# TC37XPD register map
Vendor: Infineon; Series: ATVMC; File version: 100
CPU: other r0p0, little endian, MPU, FPU, vendor SysTick, 4 interrupt priority bits
Registers are 32-bit, read-write, reset 0x0 unless marked. A register's access mark holds for its fields unless they carry their own. Offsets are from the block's base; [hi:lo] are bit positions; {n}, {i} and the like mark numbered series.

## CCU60 — CCU6
Base 0xF0002A00
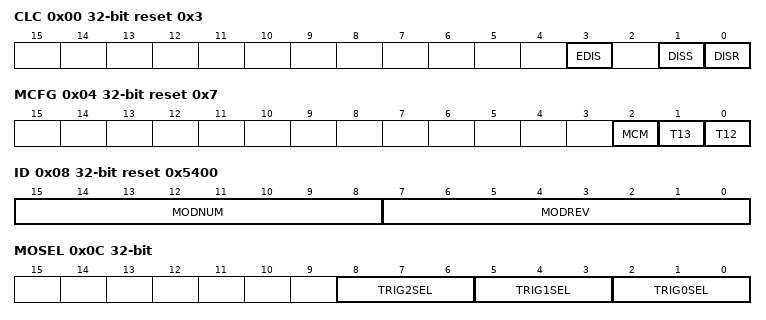
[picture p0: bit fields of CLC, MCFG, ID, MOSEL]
0x00 CLC access per field reset 0x3 — Clock Control Register resetvalue={Application Reset:0x3}
  [3] EDIS rw — Sleep Mode Enable Control EDIS. Used to control module 8217 s sleep mode.
  [1] DISS ro — Module Disable Status Bit DISS. Bit indicates the current status of the module.
  [0] DISR rw — Module Disable Request Bit DISR. Used for enable disable control of the module.
0x04 MCFG ro reset 0x7 — Module Configuration Register resetvalue={Application Reset:0x08007,Application Reset:0x7}
  [2] MCM — Multi Channel Mode Available MCM. This bit indicates if the multi channel mode functionality is available.
  [1] T13 — T13 Available T13. This bit indicates if the T13 block is available.
  [0] T12 — T12 Available T12. This bit indicates if the T12 block is available.
0x08 ID ro reset 0x5400 (reset mask 0xFFFFFF00) — Module Identification Register resetvalue={Application Reset:0x5400,Application Reset:0x5409}
  [15:8] MODNUM — Module Number Value MODNUM. This bit field defines the module identification number for the CCU6 54 H
  [7:0] MODREV — Module Revision Number MODREV. MODREV defines the module revision number. The value of a module revision starts with 01 H first revision 02 H 03 H 8230 up to FF H .
0x0C MOSEL — CCU60 Module Output Select Register resetvalue={Application Reset:0x0}
  [8:6] TRIG2SEL — Output Trigger Select for CCU6061 TRIG2. This bit field defines the output signal from the CCU6061 module used as the trigger signal to the EVADC inputs.
  [5:3] TRIG1SEL — Output Trigger Select for CCU6061 TRIG2. This bit field defines the output signal from the CCU6061 module used as the trigger signal to the EVADC inputs.
  [2:0] TRIG0SEL — Output Trigger Select for CCU6061 TRIG2. This bit field defines the output signal from the CCU6061 module used as the trigger signal to the EVADC inputs.
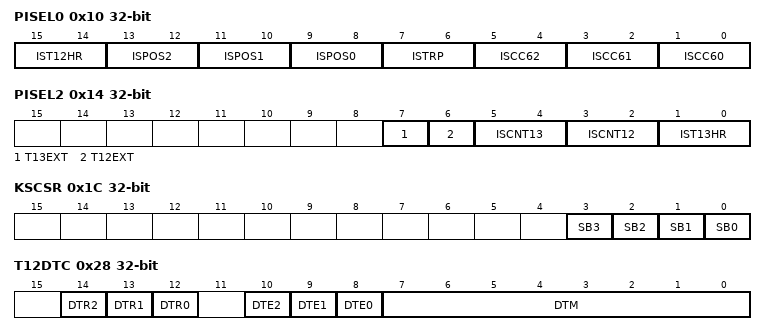
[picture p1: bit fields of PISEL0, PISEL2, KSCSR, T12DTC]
0x10 PISEL0 — Port Input Select Register 0 resetvalue={Application Reset:0x0}
  [15:14] IST12HR — Input Select for T12HR IST12HR. This bit field defines the input signal used as T12HR input.
  [13:12] ISPOS2 — Input Select for CCPOS0 ISPOSx x 0 1 2 . This bit field defines the input signal used as CCPOSx input.
  [11:10] ISPOS1 — Input Select for CCPOS0 ISPOSx x 0 1 2 . This bit field defines the input signal used as CCPOSx input.
  [9:8] ISPOS0 — Input Select for CCPOS0 ISPOSx x 0 1 2 . This bit field defines the input signal used as CCPOSx input.
  [7:6] ISTRP — Input Select for CTRAP ISTRP. This bit field defines the input signal used as CTRAP input.
  [5:4] ISCC62 — Input Select for CC60 ISCC6x x 0 1 2 . This bit field defines the input signal used as CC6x capture input.
  [3:2] ISCC61 — Input Select for CC60 ISCC6x x 0 1 2 . This bit field defines the input signal used as CC6x capture input.
  [1:0] ISCC60 — Input Select for CC60 ISCC6x x 0 1 2 . This bit field defines the input signal used as CC6x capture input.
0x14 PISEL2 — Port Input Select Register 2 resetvalue={Application Reset:0x0}
  [7] T13EXT — Extension for T13HR Inputs T13EXT. This bit extends the 2 bit field IST13HR.
  [6] T12EXT — Extension for T12HR Inputs T12EXT. This bit extends the 2 bit field IST12HR.
  [5:4] ISCNT13 — Input Select for T13 Counting Input ISCNT13. This bit field defines the input event leading to a counting action of T13.
  [3:2] ISCNT12 — Input Select for T12 Counting Input ISCNT12. This bit field defines the input event leading to a counting action of T12.
  [1:0] IST13HR — Input Select for T13HR IST13HR. This bit field defines the input signal used as T13HR input.
0x1C KSCSR — Kernel State Control Sensitivity Register resetvalue={PowerOn Reset:0x0,Debug Reset:0x0}
  [n] SB{n} (n=0..3) — Sensitivity Block x SBx x 0 1 2 3 . This bit defines if block x of the CCU6 kernel is sensitive to Stop Mode 0 or Stop Mode 1. The functional definition of the blocks is given in CROSSREFERENCE .
0x20 T12 — Timer T12 Counter Register resetvalue={Application Reset:0x0}
  [15:0] T12CV — Timer 12 Counter Value T12CV. This register represents the 16 bit counter value of Timer12.
0x24 T12PR — Timer 12 Period Register resetvalue={Application Reset:0x0}
  [15:0] T12PV — T12 Period Value T12PV. The value T12PV defines the counter value for T12 leading to a period match. When reaching this value the timer T12 is set to zero edge aligned mode or changes its count direction to down counting center aligned mode .
0x28 T12DTC access per field — Dead Time Control Register for Timer12 resetvalue={Application Reset:0x0}
  [14] DTR2 ro — Dead Time Run Indication Bits DTRx x 1 2 3 . Bits DTR0 8230 DTR2 indicate the status of the dead time generation for each compare channel 0 1 2 of timer T12.
  [13] DTR1 ro — Dead Time Run Indication Bits DTRx x 1 2 3 . Bits DTR0 8230 DTR2 indicate the status of the dead time generation for each compare channel 0 1 2 of timer T12.
  [12] DTR0 ro — Dead Time Run Indication Bits DTRx x 1 2 3 . Bits DTR0 8230 DTR2 indicate the status of the dead time generation for each compare channel 0 1 2 of timer T12.
  [10] DTE2 rw — Dead Time Enable Bits DTEx x 0 1 2 . Bits DTE0 8230 DTE2 enable and disable the dead time generation for each compare channel 0 1 2 of timer T12.
  [9] DTE1 rw — Dead Time Enable Bits DTEx x 0 1 2 . Bits DTE0 8230 DTE2 enable and disable the dead time generation for each compare channel 0 1 2 of timer T12.
  [8] DTE0 rw — Dead Time Enable Bits DTEx x 0 1 2 . Bits DTE0 8230 DTE2 enable and disable the dead time generation for each compare channel 0 1 2 of timer T12.
  [7:0] DTM rw — Dead Time DTM. Bit field DTM determines the programmable delay between switching from the passive state to the active state of the selected outputs. The switching from the active state to the passive state is not delayed.
{0x30+4i} CC6xR[{i}] (i=0..2) ro — Capture Compare Register for Channel CC60 resetvalue={Application Reset:0x0}
  [15:0] CCV — Capture Compare Value CCV. In compare mode the bit fields CCV contain the values that are compared to the T12 counter value. In capture mode the captured value of T12 can be read from these registers.
{0x40+4i} CC6xSR[{i}] (i=0..2) — Capture Compare Shadow Reg. for Channel CC60 resetvalue={Application Reset:0x0}
  [15:0] CCS — Shadow Register for Channel x Capture Compare Value CCS. In compare mode the bit fields contents of CCS are transferred to the bit fields CCV for the corresponding channel during a shadow transfer. In capture mode the captured value of T12 can be read from these registers.
0x50 T13 — Timer T13 Counter Register resetvalue={Application Reset:0x0}
  [15:0] T13CV — Timer 13 Counter Value T13CV. This register represents the 16 bit counter value of Timer13.
0x54 T13PR — Timer 13 Period Register resetvalue={Application Reset:0x0}
  [15:0] T13PV — T13 Period Value T13PV. The value T13PV defines the counter value for T13 leading to a period match. When reaching this value the timer T13 is set to zero.
0x58 CC63R ro — Compare Register for T13 resetvalue={Application Reset:0x0}
  [15:0] CCV — Channel CC63 Compare Value CCV. The bit field CCV contains the value that is compared to the T13 counter value.
0x5C CC63SR — Compare Shadow Register for T13 resetvalue={Application Reset:0x0}
  [15:0] CCS — Shadow Register for Channel CC63 Compare Value CCS. The bit field contents of CCS is transferred to the bit field CCV during a shadow transfer.
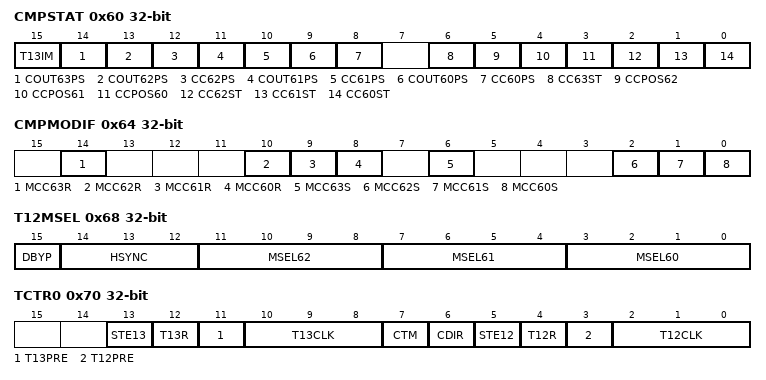
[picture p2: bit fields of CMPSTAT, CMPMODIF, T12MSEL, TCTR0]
0x60 CMPSTAT access per field — Compare State Register resetvalue={Application Reset:0x0}
  [15] T13IM rw — T13 Inverted Modulation T13IM. Bit T13IM inverts the T13 signal for the modulation of the CC6x and COUT6x x 0 1 2 signals.
  [14] COUT63PS rw — Passive State Select for Compare Output COUT63 COUT63PS. Bit COUT63PS selects the state of the corresponding compare channel that is considered to be the passive state. During the passive state the passive level defined in register PSLR is driven by the output pin. Bit COUT63PS is related to T13.
  [13] COUT62PS rw — Passive State Select for Compare Outputs COUT62 x 0 1 2 COUT62PS. Bits COUT6xPS select the state of the corresponding compare channel that is considered to be the passive state. During the passive state the passive level defined in register PSLR is driven by the output pin. Bits COUT6xPS x 0 1 2 are related to T12. In capture mode these bits are not used.
  [12] CC62PS rw — Passive State Select for Compare Outputs CC62 x 0 1 2 CC62PS. Bits CC6xPS select the state of the corresponding compare channel that is considered to be the passive state. During the passive state the passive level defined in register PSLR is driven by the output pin. Bits CC6xPS x 0 1 2 are related to T12. In capture mode these bits are not used.
  [11] COUT61PS rw — Passive State Select for Compare Outputs COUT62 x 0 1 2 COUT62PS. Bits COUT6xPS select the state of the corresponding compare channel that is considered to be the passive state. During the passive state the passive level defined in register PSLR is driven by the output pin. Bits COUT6xPS x 0 1 2 are related to T12. In capture mode these bits are not used.
  [10] CC61PS rw — Passive State Select for Compare Outputs CC62 x 0 1 2 CC62PS. Bits CC6xPS select the state of the corresponding compare channel that is considered to be the passive state. During the passive state the passive level defined in register PSLR is driven by the output pin. Bits CC6xPS x 0 1 2 are related to T12. In capture mode these bits are not used.
  [9] COUT60PS rw — Passive State Select for Compare Outputs COUT62 x 0 1 2 COUT62PS. Bits COUT6xPS select the state of the corresponding compare channel that is considered to be the passive state. During the passive state the passive level defined in register PSLR is driven by the output pin. Bits COUT6xPS x 0 1 2 are related to T12. In capture mode these bits are not used.
  [8] CC60PS rw — Passive State Select for Compare Outputs CC62 x 0 1 2 CC62PS. Bits CC6xPS select the state of the corresponding compare channel that is considered to be the passive state. During the passive state the passive level defined in register PSLR is driven by the output pin. Bits CC6xPS x 0 1 2 are related to T12. In capture mode these bits are not used.
  [6] CC63ST ro — Capture Compare State Bit for CC63 CC63ST. Bit CC63ST monitors the state of the compare channel. Bit CC63ST is related to T13 and is set and cleared according to the T13 switching rules.
  [5] CCPOS62 ro — Sampled Hall Pattern Bits CCPOS62. Bits CCPOS6x x 0 1 2 are indicating the value of the input Hall pattern that has been compared to the current and expected value. The value is sampled when the event HCRDY Hall Compare Ready occurs.
  [4] CCPOS61 ro — Sampled Hall Pattern Bits CCPOS62. Bits CCPOS6x x 0 1 2 are indicating the value of the input Hall pattern that has been compared to the current and expected value. The value is sampled when the event HCRDY Hall Compare Ready occurs.
  [3] CCPOS60 ro — Sampled Hall Pattern Bits CCPOS62. Bits CCPOS6x x 0 1 2 are indicating the value of the input Hall pattern that has been compared to the current and expected value. The value is sampled when the event HCRDY Hall Compare Ready occurs.
  [2] CC62ST ro — Capture Compare State Bits for CC62 x 0 1 2 CC62ST. Bits CC6xST monitor the state of the capture compare channels. Bits CC6xST x 160 160 0 1 2 are related to T12 and are set and cleared according to the T12 switching rules.
  [1] CC61ST ro — Capture Compare State Bits for CC62 x 0 1 2 CC62ST. Bits CC6xST monitor the state of the capture compare channels. Bits CC6xST x 160 160 0 1 2 are related to T12 and are set and cleared according to the T12 switching rules.
  [0] CC60ST ro — Capture Compare State Bits for CC62 x 0 1 2 CC62ST. Bits CC6xST monitor the state of the capture compare channels. Bits CC6xST x 160 160 0 1 2 are related to T12 and are set and cleared according to the T12 switching rules.
0x64 CMPMODIF wo — Compare State Modification Register resetvalue={Application Reset:0x0}
  [14] MCC63R — Capture Compare Status Modification Bits MCC63R MCC63R. This bit is used to clear the corresponding bit CC63ST by SW. The functionality of a write access to bits concerning the same capture compare state bit is shown in CROSSREFERENCE .
  [10] MCC62R — Capture Compare Status Modification Bits MCC62R x 0 1 2 MCC62R. These bits are used to clear the corresponding bits CC6xST by SW. The functionality of a write access to bits concerning the same capture compare state bit is shown in CROSSREFERENCE .
  [9] MCC61R — Capture Compare Status Modification Bits MCC62R x 0 1 2 MCC62R. These bits are used to clear the corresponding bits CC6xST by SW. The functionality of a write access to bits concerning the same capture compare state bit is shown in CROSSREFERENCE .
  [8] MCC60R — Capture Compare Status Modification Bits MCC62R x 0 1 2 MCC62R. These bits are used to clear the corresponding bits CC6xST by SW. The functionality of a write access to bits concerning the same capture compare state bit is shown in CROSSREFERENCE .
  [6] MCC63S — Capture Compare Status Modification Bit MCC63S MCC63S. This bit is used to set the corresponding bit CC63ST by SW. The functionality of a write access to bits concerning the same capture compare state bit is shown in CROSSREFERENCE .
  [2] MCC62S — Capture Compare Status Modification Bits MCC62S x 0 1 2 MCC62S. These bits are used to set the corresponding bits CC6xST by SW. The functionality of a write access to bits concerning the same capture compare state bit is shown in CROSSREFERENCE .
  [1] MCC61S — Capture Compare Status Modification Bits MCC62S x 0 1 2 MCC62S. These bits are used to set the corresponding bits CC6xST by SW. The functionality of a write access to bits concerning the same capture compare state bit is shown in CROSSREFERENCE .
  [0] MCC60S — Capture Compare Status Modification Bits MCC62S x 0 1 2 MCC62S. These bits are used to set the corresponding bits CC6xST by SW. The functionality of a write access to bits concerning the same capture compare state bit is shown in CROSSREFERENCE .
0x68 T12MSEL — T12 Mode Select Register resetvalue={Application Reset:0x0}
  [15] DBYP — Delay Bypass DBYP. DBYP controls whether the source signal for the sampling of the Hall input pattern selected by HSYNC is delayed by the Dead Time Counter 0.
  [14:12] HSYNC — Hall Synchronization HSYNC. Bit field HSYNC defines the source for the sampling of the Hall input pattern and the comparison to the current and the expected Hall pattern bit fields. Coding see CROSSREFERENCE .
  [11:8] MSEL62 — Capture Compare Mode Selection MSEL6x x 0 1 2 . These bit fields select the operating mode of the three T12 capture compare channels. Each channel x 0 1 2 can be programmed individually for one of these modes except for Hall Sensor Mode . Coding see CROSSREFERENCE .
  [7:4] MSEL61 — Capture Compare Mode Selection MSEL6x x 0 1 2 . These bit fields select the operating mode of the three T12 capture compare channels. Each channel x 0 1 2 can be programmed individually for one of these modes except for Hall Sensor Mode . Coding see CROSSREFERENCE .
  [3:0] MSEL60 — Capture Compare Mode Selection MSEL6x x 0 1 2 . These bit fields select the operating mode of the three T12 capture compare channels. Each channel x 0 1 2 can be programmed individually for one of these modes except for Hall Sensor Mode . Coding see CROSSREFERENCE .
0x70 TCTR0 access per field — Timer Control Register 0 resetvalue={Application Reset:0x0}
  [13] STE13 ro — Timer T13 Shadow Transfer Enable STE13. Bit STE13 enables or disables the shadow transfer of the T13 period value the compare value and passive state select bit and level from their shadow registers to the actual registers if a T13 shadow transfer event is detected. Bit STE13 is cleared by hardware after the shadow transfer. A T13 shadow transfer event is a period match.
  [12] T13R ro — Timer T13 Run Bit T13R. T13R starts and stops timer T13. It is set cleared by SW by setting bits T13RR orT13RS or it is set cleared by HW according to the function defined by bit fields T13SSC T13TEC and T13TED.
  [11] T13PRE rw — Timer T13 Prescaler Bit T13PRE. In order to support higher clock frequencies an additional prescaler factor of 1 256 can be enabled for the prescaler for T13.
  [10:8] T13CLK rw — Timer T13 Input Clock Select T13CLK. Selects the input clock for timer T13 that is derived from the peripheral clock according to the equation f T13 f CC6 2 lt T13CLK gt .
  [7] CTM rw — T12 Operating Mode CTM
  [6] CDIR ro — Count Direction of Timer T12 CDIR. This bit is set cleared according to the counting rules of T12.
  [5] STE12 ro — Timer T12 Shadow Transfer Enable STE12. Bit STE12 enables or disables the shadow transfer of the T12 period value the compare values and passive state select bits and levels from their shadow registers to the actual registers if a T12 shadow transfer event is detected. Bit STE12 is cleared by hardware after the shadow transfer. A T12 shadow transfer event is a period match while counting up or a one match while counting down.
  [4] T12R ro — Timer T12 Run Bit T12R. T12R starts and stops timer T12. It is set cleared by SW by setting bits T12RR or T12RS or it is cleared by HW according to the function defined by bit field T12SSC.
  [3] T12PRE rw — Timer T12 Prescaler Bit T12PRE. In order to support higher clock frequencies an additional prescaler factor of 1 256 can be enabled for the prescaler for T12.
  [2:0] T12CLK rw — Timer T12 Input Clock Select T12CLK. Selects the input clock for timer T12 that is derived from the peripheral clock according to the equation f T12 f CC6 2 lt T12CLK gt .
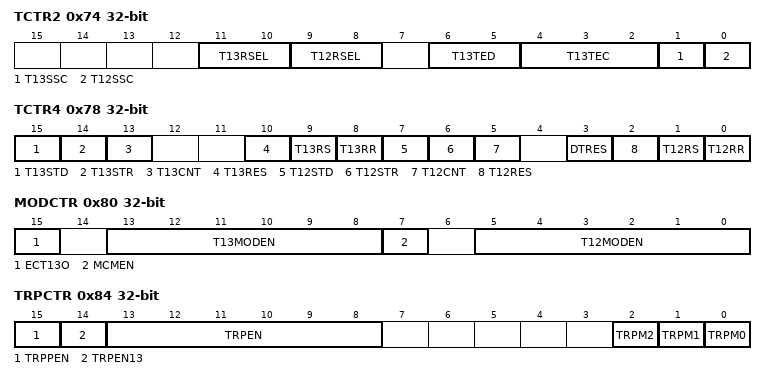
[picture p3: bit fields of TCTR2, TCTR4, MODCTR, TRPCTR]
0x74 TCTR2 — Timer Control Register 2 resetvalue={Application Reset:0x0}
  [11:10] T13RSEL — Timer T13 External Run Selection T13RSEL. Bit field T13RSEL defines the event of signal T13HR that can set the run bit T13R by HW.
  [9:8] T12RSEL — Timer T12 External Run Selection T12RSEL. Bit field T12RSEL defines the event of signal T12HR that can set the run bit T12R by HW.
  [6:5] T13TED — Timer T13 Trigger Event Direction T13TED. Bit field T13TED delivers additional information to control the automatic set of bit T13R in the case that the trigger action defined by T13TEC is detected.
  [4:2] T13TEC — T13 Trigger Event Control T13TEC. Bit field T13TEC selects the trigger event to start T13 automatic set of T13R for synchronization to T12 compare signals according to following combinations
  [1] T13SSC — Timer T13 Single Shot Control T13SSC. This bit controls the single shot mode of T13.
  [0] T12SSC — Timer T12 Single Shot Control T12SSC. This bit controls the single shot mode of T12.
0x78 TCTR4 wo — Timer Control Register 4 resetvalue={Application Reset:0x0}
  [15] T13STD — Timer T13 Shadow Transfer Disable T13STD
  [14] T13STR — Timer T13 Shadow Transfer Request T13STR
  [13] T13CNT — Timer T13 Count Event T13CNT
  [10] T13RES — Timer T13 Reset T13RES
  [9] T13RS — Timer T13 Run Set T13RS. Setting this bit sets the T13R bit.
  [8] T13RR — Timer T13 Run Reset T13RR. Setting this bit clears the T13R bit.
  [7] T12STD — Timer T12 Shadow Transfer Disable T12STD
  [6] T12STR — Timer T12 Shadow Transfer Request T12STR
  [5] T12CNT — Timer T12 Count Event T12CNT
  [3] DTRES — Dead Time Counter Reset DTRES
  [2] T12RES — Timer T12 Reset T12RES
  [1] T12RS — Timer T12 Run Set T12RS. Setting this bit sets the T12R bit.
  [0] T12RR — Timer T12 Run Reset T12RR. Setting this bit clears the T12R bit.
0x80 MODCTR — Modulation Control Register resetvalue={Application Reset:0x0}
  [15] ECT13O — Enable Compare Timer T13 Output ECT13O
  [13:8] T13MODEN — T13 Modulation Enable T13MODEN. These bits enable the modulation of the corresponding output signal by the PWM pattern CC63 O generated by timer T13. T13MODEN0 MODCTR.8 for output CC60 T13MODEN1 MODCTR.9 for output COUT60 T13MODEN2 MODCTR.10 for output CC61 T13MODEN3 MODCTR.11 for output COUT61 T13MODEN4 MODCTR.12 for output CC62 T13MODEN5 MODCTR.13 for output COUT62
  [7] MCMEN — Multi Channel Mode Enable MCMEN
  [5:0] T12MODEN — T12 Modulation Enable T12MODEN. These bits enable the modulation of the corresponding output signal by a PWM pattern generated by timer T12. T12MODEN0 MODCTR.0 for output CC60 T12MODEN1 MODCTR.1 for output COUT60 T12MODEN2 MODCTR.2 for output CC61 T12MODEN3 MODCTR.3 for output COUT61 T12MODEN4 MODCTR.4 for output CC62 T12MODEN5 MODCTR.5 for output COUT62
0x84 TRPCTR — Trap Control Register resetvalue={Application Reset:0x0}
  [15] TRPPEN — Trap Pin Enable TRPPEN. This bit enables the input pin function for the trap generation. An interrupt can only be generated if a falling edge is detected at pin CTRAP while TRPPEN 1.
  [14] TRPEN13 — Trap Enable Control for Timer T13 TRPEN13
  [13:8] TRPEN — Trap Enable Control TRPEN. Setting a bit enables the trap functionality for the following corresponding output signals TRPEN0 TRPCTR.8 for output CC60 TRPEN1 TRPCTR.9 for output COUT60 TRPEN2 TRPCTR.10 for output CC61 TRPEN3 TRPCTR.11 for output COUT61 TRPEN4 TRPCTR.12 for output CC62 TRPEN5 TRPCTR.13 for output COUT62
  [2] TRPM2 — Trap Mode Control Bit 2 TRPM2. This bit defines how the trap flag TRPF can be cleared after the trap input condition CTRAP 160 160 0 and TRPPEN 160 160 1 is no longer valid either by CTRAP 160 160 1 or by TRPPEN 160 160 0 .
  [1] TRPM1 — Trap Mode Control Bit 1 TRPM1. Together with bit TRPM0 these two bits define the behavior of the selected outputs when leaving the trap state after the trap condition has become inactive again. A synchronization to the timer driving the PWM pattern avoids unintended pulses when leaving the trap state. The behavior resulting from the combination TRPM1 TRPM0 is described in CROSSREFERENCE .
  [0] TRPM0 — Trap Mode Control Bit 0 TRPM0. Together with bit TRPM1 these two bits define the behavior of the selected outputs when leaving the trap state after the trap condition has become inactive again. A synchronization to the timer driving the PWM pattern avoids unintended pulses when leaving the trap state. The behavior resulting from the combination TRPM1 TRPM0 is described in CROSSREFERENCE .
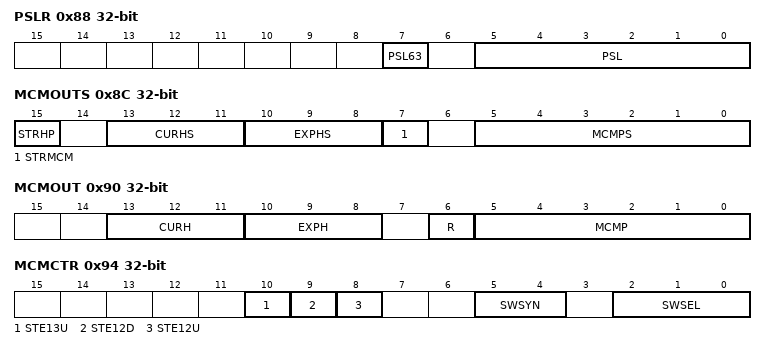
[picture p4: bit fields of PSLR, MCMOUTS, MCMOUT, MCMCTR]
0x88 PSLR — Passive State Level Register resetvalue={Application Reset:0x0}
  [7] PSL63 — Passive State Level of Output COUT63 PSL63. This bit defines the passive level driven by the module output COUT63 during the passive state.
  [5:0] PSL — Compare Outputs Passive State Level PSL. These bits define the passive level driven by the module outputs during the passive state. PSL0 PSLR.0 for output CC60 PSL1 PSLR.1 for output COUT60 PSL2 PSLR.2 for output CC61 PSL3 PSLR.3 for output COUT61 PSL4 PSLR.4 for output CC62 PSL5 PSLR.5 for output COUT62
0x8C MCMOUTS access per field — Multi Channel Mode Output Shadow Register resetvalue={Application Reset:0x0}
  [15] STRHP wo — Shadow Transfer Request for the Hall Pattern STRHP. Writing STRHP 1 leads to an immediate activation of HP ST to update bit fields EXPH and CURH by EXPHS and CURHS. When read this bit always delivers 0.
  [13:11] CURHS rw — Current Hall Pattern Shadow CURHS. Bit field CURHS is the shadow bit field for bit field CURH. The shadow transfer takes place when a correct Hall event is detected CM CHE .
  [10:8] EXPHS rw — Expected Hall Pattern Shadow EXPHS. Bit field EXPHS is the shadow bit field for bit field EXPH. The shadow transfer takes place when a correct Hall event is detected CM CHE .
  [7] STRMCM wo — Shadow Transfer Request for MCMPS STRMCM. Writing STRMCM 160 160 1 leads to an immediate activation of MCM ST to update bit field MCMP by the value of MCMPS. When read this bit always delivers 0.
  [5:0] MCMPS rw — Multi Channel PWM Pattern Shadow MCMPS. Bit field MCMPS is the shadow bit field for bit field MCMP. The multi channel shadow transfer is triggered by MCM ST according to the transfer conditions defined by register MCMCTR.
0x90 MCMOUT ro — Multi Channel Mode Output Register resetvalue={Application Reset:0x0}
  [13:11] CURH — Current Hall Pattern CURH. Bit field CURH is updated by a shadow transfer HP ST from bit field CURHS. If HCRDY 1 CURH is compared to the sampled CCPOSx inputs in order to detect a spike. If the sampled Hall pattern at the Hall input pins is equal to bit field CURH no Hall event has been detected. If the sampled Hall input pattern is neither equal to CURH nor equal to EXPH the Hall event was not the desired one and may be due to a fatal error e.g. blocked rotor etc. . In this case a wrong Hall event has been detected CM WHE .
  [10:8] EXPH — Expected Hall Pattern EXPH. Bit field EXPH is updated by a shadow transfer HP ST from bit field EXPHS. If HCRDY 1 EXPH is compared to the sampled CCPOSx inputs in order to detect the occurrence of the next desired expected hall pattern or a wrong pattern. If the sampled hall pattern at the hall input pins is equal to bit field EXPH a correct Hall event has been detected CM CHE .
  [6] R — Reminder Flag R. This flag indicates that the shadow transfer from MCMPS to MCMP has been requested by the selected trigger source. It is cleared when the shadow transfer takes place or while MCMEN 0.
  [5:0] MCMP — Multi Channel PWM Pattern MCMP. Bit field MCMP defines the output pattern for the multi channel mode. If this mode is enabled by MODCTR.MCMEN 1 the output state of all T12 related PWM outputs can be modified. This bit field is 0 while IS.IDLE 1. MCMP0 MCMOUT.0 for output CC60 MCMP1 MCMOUT.1 for output COUT60 MCMP2 MCMOUT.2 for output CC61 MCMP3 MCMOUT.3 for output COUT61 MCMP4 MCMOUT.4 for output CC62 MCMP5 MCMOUT.5 for output COUT62
0x94 MCMCTR — Multi Channel Mode Control Register resetvalue={Application Reset:0x0}
  [10] STE13U — Shadow Transfer Enable for T13 Upcounting STE13U. This bit enables the shadow transfer T13 ST if flag MCMOUT.R is set or becomes set while a T13 period match is detected.
  [9] STE12D — Shadow Transfer Enable for T12 Downcounting STE12D. This bit enables the shadow transfer T12 ST if flag MCMOUT.R is set or becomes set while a T12 one match is detected while counting down.
  [8] STE12U — Shadow Transfer Enable for T12 Upcounting STE12U. This bit enables the shadow transfer T12 ST if flag MCMOUT.R is set or becomes set while a T12 period match is detected while counting up.
  [5:4] SWSYN — Switching Synchronization SWSYN. Bit field SWSYN defines the synchronization mechanism of the shadow transfer event MCM ST if it has been requested before flag R set by an event selected by SWSEL and if MCMEN 1. This feature permits the synchronization of the outputs to the PWM source that is used for modulation T12 or T13 .
  [2:0] SWSEL — Switching Selection SWSEL. Bit field SWSEL selects one of the following trigger request sources next multi channel event for the shadow transfer MCM ST from MCMPS to MCMP. The trigger request is stored in the reminder flag R until the shadow transfer is done and flag R is cleared automatically with the shadow transfer. The shadow transfer takes place synchronously with an event selected in bit field SWSYN.
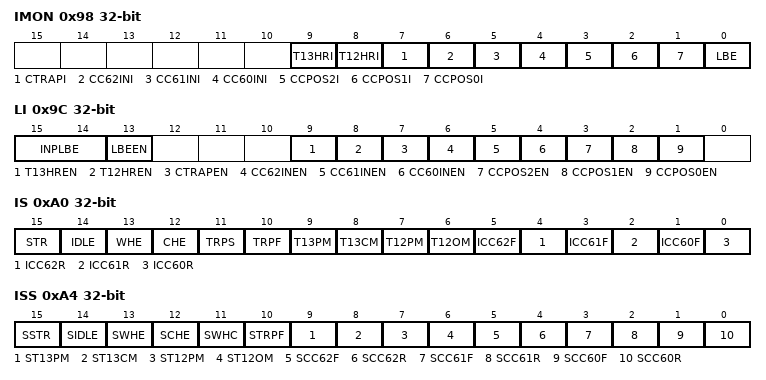
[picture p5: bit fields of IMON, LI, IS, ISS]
0x98 IMON — Input Monitoring Register resetvalue={Application Reset:0x0}
  [9] T13HRI — Event indication for input signal T13HR T13HRI. The bit determines if the selected event has occurred via an edge detection. The bit can be cleared by writing a 1 to the same bit position while writing a 0 has no effect.
  [8] T12HRI — Event indication for input signal T12HR T12HRI. The bit determines if the selected event has occurred via an edge detection. The bit can be cleared by writing a 1 to the same bit position while writing a 0 has no effect.
  [7] CTRAPI — Event indication for input signal CTRAP CTRAPI. The bit determines if the selected event has occurred via an edge detection. The bit can be cleared by writing a 1 to the same bit position while writing a 0 has no effect.
  [6] CC62INI — Event indication for input signal CC62IN CC62INI. The bit determines if the selected event has occurred via an edge detection. The bit can be cleared by writing a 1 to the same bit position while writing a 0 has no effect.
  [5] CC61INI — Event indication for input signal CC62IN CC62INI. The bit determines if the selected event has occurred via an edge detection. The bit can be cleared by writing a 1 to the same bit position while writing a 0 has no effect.
  [4] CC60INI — Event indication for input signal CC62IN CC62INI. The bit determines if the selected event has occurred via an edge detection. The bit can be cleared by writing a 1 to the same bit position while writing a 0 has no effect.
  [3] CCPOS2I — Event indication for input signal CCPOS2 CCPOS2I. The bit determines if the selected event has occurred via an edge detection. The bit can be cleared by writing a 1 to the same bit position while writing a 0 has no effect. The dedicated edge is indicated for a selected event if Hysteretic like Control or Capture modes are initialized in T12MSEL.MSEL6x. If these modes are not selected then all edges will be indicated as an event for the inputs.
  [2] CCPOS1I — Event indication for input signal CCPOS2 CCPOS2I. The bit determines if the selected event has occurred via an edge detection. The bit can be cleared by writing a 1 to the same bit position while writing a 0 has no effect. The dedicated edge is indicated for a selected event if Hysteretic like Control or Capture modes are initialized in T12MSEL.MSEL6x. If these modes are not selected then all edges will be indicated as an event for the inputs.
  [1] CCPOS0I — Event indication for input signal CCPOS2 CCPOS2I. The bit determines if the selected event has occurred via an edge detection. The bit can be cleared by writing a 1 to the same bit position while writing a 0 has no effect. The dedicated edge is indicated for a selected event if Hysteretic like Control or Capture modes are initialized in T12MSEL.MSEL6x. If these modes are not selected then all edges will be indicated as an event for the inputs.
  [0] LBE — Lost Bit Event LBE. This bit determines if a lost bit event has occurred. A lost bit event occurs when a selected event occurs again with the previous event captured IMON.x remains set and its lost indicator is enabled for at least one of the monitored input signals. The bit can be cleared by writing a 1 to the same bit position while writing a 0 has no effect.
0x9C LI — Lost Indicator Register resetvalue={Application Reset:0x0}
  [15:14] INPLBE — Interrupt Node Pointer for lost bit event INPLBE. This bit field defines which service request output line is selected to output an lost event alert for an enabled lost bit event.
  [13] LBEEN — Interrupt Enable for Lost Bit Event LBEEN. This bit determines if a SRx line is activated if lost bit event is detected.
  [9] T13HREN — Lost Indicator Enable for input signal T13HR T13HREN. This bit determines if the monitored event at the input signal is enabled for the detection of a lost bit event.
  [8] T12HREN — Lost Indicator Enable for input signal T12HR T12HREN. This bit determines if the monitored event at the input signal is enabled for the detection of a lost bit event.
  [7] CTRAPEN — Lost Indicator Enable for input signal CTRAP CTRAPEN. This bit determines if the monitored event at the input signal is enabled for the detection of a lost bit event.
  [6] CC62INEN — Lost Indicator Enable for input signal CC62IN CC62INEN. This bit determines if the monitored event at the input signal is enabled for the detection of a lost bit event.
  [5] CC61INEN — Lost Indicator Enable for input signal CC62IN CC62INEN. This bit determines if the monitored event at the input signal is enabled for the detection of a lost bit event.
  [4] CC60INEN — Lost Indicator Enable for input signal CC62IN CC62INEN. This bit determines if the monitored event at the input signal is enabled for the detection of a lost bit event.
  [3] CCPOS2EN — Lost Indicator Enable for input signal CCPOS2 CCPOS2EN. This bit determines if the monitored event at the input signal is enabled for the detection of a lost bit event.
  [2] CCPOS1EN — Lost Indicator Enable for input signal CCPOS2 CCPOS2EN. This bit determines if the monitored event at the input signal is enabled for the detection of a lost bit event.
  [1] CCPOS0EN — Lost Indicator Enable for input signal CCPOS2 CCPOS2EN. This bit determines if the monitored event at the input signal is enabled for the detection of a lost bit event.
0xA0 IS ro — Interrupt Status Register resetvalue={Application Reset:0x0}
  [15] STR — Multi Channel Mode Shadow Transfer Request STR. This bit indicates that a shadow transfer from MCMPS to MCMP MCM ST has taken place.
  [14] IDLE — IDLE State IDLE. If enabled by ENIDLE 1 this bit is set together with bit WHE and it has to be cleared by SW.
  [13] WHE — Wrong Hall Event WHE. This bit indicates that a wrong Hall event CM WHE has been detected.
  [12] CHE — Correct Hall Event CHE. This bit indicates that a correct Hall event CM CHE has been detected.
  [11] TRPS — Trap State TRPS. This bit indicates the actual trap state. It is set if TRPF 1 and becomes cleared according to the mode selected in register TRPCTR.
  [10] TRPF — Trap Flag TRPF. This bit indicates if a trap condition input CTRAP 0 or by SW is has been detected. If TRPM2 0 it becomes cleared automatically if CTRAP 1 or TRPPEN 0 whereas if TRPM2 1 it has to be cleared by writing RTRPF 1.
  [9] T13PM — Timer T13 Period Match Flag T13PM. This bit indicates that a timer T13 period match T13 PM has been detected.
  [8] T13CM — Timer T13 Compare Match Flag T13CM. This bit indicates that a timer T13 compare match CM 63 has been detected.
  [7] T12PM — Timer T12 Period Match Flag T12PM. This bit indicates that a timer T12 period match while counting up T12 PM and CDIR 0 has been detected.
  [6] T12OM — Timer T12 One Match Flag T12OM. This bit indicates that a timer T12 one match while counting down T12 OM and CDIR 1 has been detected.
  [5] ICC62F — Capture Compare Match Falling Edge Flag ICC6xF x 0 1 2 . This bit indicates that event CC6x F has been detected. This event occurs in compare mode when a compare match is detected while T12 is counting down CM 6x and CDIR 160 160 1 and in capture mode when a falling edge is detected at the related input CC6xIN.
  [4] ICC62R — Capture Compare Match Rising Edge Flag ICC6xR x 0 1 2 . This bit indicates that event CC6x R has been detected. This event occurs in compare mode when a compare match is detected while T12 is counting up CM 6x and CDIR 160 160 0 and in capture mode when a rising edge is detected at the related input CC6xIN.
  [3] ICC61F — Capture Compare Match Falling Edge Flag ICC6xF x 0 1 2 . This bit indicates that event CC6x F has been detected. This event occurs in compare mode when a compare match is detected while T12 is counting down CM 6x and CDIR 160 160 1 and in capture mode when a falling edge is detected at the related input CC6xIN.
  [2] ICC61R — Capture Compare Match Rising Edge Flag ICC6xR x 0 1 2 . This bit indicates that event CC6x R has been detected. This event occurs in compare mode when a compare match is detected while T12 is counting up CM 6x and CDIR 160 160 0 and in capture mode when a rising edge is detected at the related input CC6xIN.
  [1] ICC60F — Capture Compare Match Falling Edge Flag ICC6xF x 0 1 2 . This bit indicates that event CC6x F has been detected. This event occurs in compare mode when a compare match is detected while T12 is counting down CM 6x and CDIR 160 160 1 and in capture mode when a falling edge is detected at the related input CC6xIN.
  [0] ICC60R — Capture Compare Match Rising Edge Flag ICC6xR x 0 1 2 . This bit indicates that event CC6x R has been detected. This event occurs in compare mode when a compare match is detected while T12 is counting up CM 6x and CDIR 160 160 0 and in capture mode when a rising edge is detected at the related input CC6xIN.
0xA4 ISS wo — Interrupt Status Set Register resetvalue={Application Reset:0x0}
  [15] SSTR — Set STR Flag SSTR
  [14] SIDLE — Set IDLE Flag SIDLE
  [13] SWHE — Set Wrong Hall Event Flag SWHE
  [12] SCHE — Set Correct Hall Event Flag SCHE
  [11] SWHC — Software Hall Compare SWHC
  [10] STRPF — Set Trap Flag STRPF
  [9] ST13PM — Set Timer T13 Period Match Flag ST13PM
  [8] ST13CM — Set Timer T13 Compare Match Flag ST13CM
  [7] ST12PM — Set Timer T12 Period Match Flag ST12PM
  [6] ST12OM — Set Timer T12 One Match Flag ST12OM
  [5] SCC62F — Set Capture Compare Match Falling Edge Flag SCC6xF x 0 1 2
  [4] SCC62R — Set Capture Compare Match Rising Edge Flag SCC6xR x 0 1 2
  [3] SCC61F — Set Capture Compare Match Falling Edge Flag SCC6xF x 0 1 2
  [2] SCC61R — Set Capture Compare Match Rising Edge Flag SCC6xR x 0 1 2
  [1] SCC60F — Set Capture Compare Match Falling Edge Flag SCC6xF x 0 1 2
  [0] SCC60R — Set Capture Compare Match Rising Edge Flag SCC6xR x 0 1 2
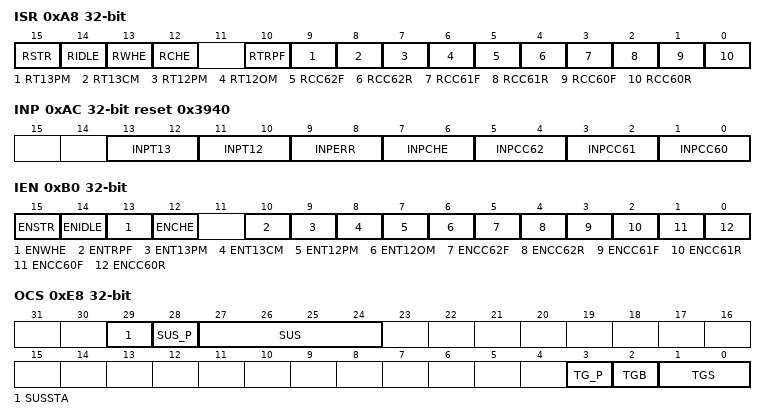
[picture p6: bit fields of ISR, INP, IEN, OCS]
0xA8 ISR wo — Interrupt Status Reset Register resetvalue={Application Reset:0x0}
  [15] RSTR — Reset STR Flag RSTR
  [14] RIDLE — Reset IDLE Flag RIDLE
  [13] RWHE — Reset Wrong Hall Event Flag RWHE
  [12] RCHE — Reset Correct Hall Event Flag RCHE
  [10] RTRPF — Reset Trap Flag RTRPF
  [9] RT13PM — Reset Timer T13 Period Match Flag RT13PM
  [8] RT13CM — Reset Timer T13 Compare Match Flag RT13CM
  [7] RT12PM — Reset Timer T12 Period Match Flag RT12PM
  [6] RT12OM — Reset Timer T12 One Match Flag RT12OM
  [5] RCC62F — Reset Capture Compare Match Falling Edge Flag RCC6xF x 0 1 2
  [4] RCC62R — Reset Capture Compare Match Rising Edge Flag RCC6xR x 0 1 2
  [3] RCC61F — Reset Capture Compare Match Falling Edge Flag RCC6xF x 0 1 2
  [2] RCC61R — Reset Capture Compare Match Rising Edge Flag RCC6xR x 0 1 2
  [1] RCC60F — Reset Capture Compare Match Falling Edge Flag RCC6xF x 0 1 2
  [0] RCC60R — Reset Capture Compare Match Rising Edge Flag RCC6xR x 0 1 2
0xAC INP reset 0x3940 — Interrupt Node Pointer Register resetvalue={Application Reset:0x3940}
  [13:12] INPT13 — Interrupt Node Pointer for Timer13 Interrupt INPT13. This bit field defines the service request output activated due to a set condition for bit T13CM if enabled by bit ENT13CM or for bit T13PM if enabled by bit ENT13PM . Coding see INPCC6x.
  [11:10] INPT12 — Interrupt Node Pointer for Timer12 Interrupts INPT12. This bit field defines the service request output activated due to a set condition for bit T12OM if enabled by bit ENT12OM or for bit T12PM if enabled by bit ENT12PM . Coding see INPCC6x.
  [9:8] INPERR — Interrupt Node Pointer for Error Interrupts INPERR. This bit field defines the service request output activated due to a set condition for bit TRPF if enabled by bit ENTRPF or for bit WHE if enabled by bit ENWHE . Coding see INPCC6x.
  [7:6] INPCHE — Interrupt Node Pointer for the CHE Interrupt INPCHE. This bit field defines the service request output activated due to a set condition for bit CHE if enabled by bit ENCHE of for bit STR if enabled by bit ENSTR . Coding see INPCC6x.
  [5:4] INPCC62 — Interrupt Node Pointer for Channel CC6x Interrupts INPCC6x x 0 1 2 . This bit field defines the service request output activated due to a set condition for bit CC6xR if enabled by bit ENCC6xR or for bit CC6xF if enabled by bit ENCC6xF .
  [3:2] INPCC61 — Interrupt Node Pointer for Channel CC6x Interrupts INPCC6x x 0 1 2 . This bit field defines the service request output activated due to a set condition for bit CC6xR if enabled by bit ENCC6xR or for bit CC6xF if enabled by bit ENCC6xF .
  [1:0] INPCC60 — Interrupt Node Pointer for Channel CC6x Interrupts INPCC6x x 0 1 2 . This bit field defines the service request output activated due to a set condition for bit CC6xR if enabled by bit ENCC6xR or for bit CC6xF if enabled by bit ENCC6xF .
0xB0 IEN — Interrupt Enable Register resetvalue={Application Reset:0x0}
  [15] ENSTR — Enable Multi Channel Mode Shadow Transfer Interrupt ENSTR
  [14] ENIDLE — Enable Idle ENIDLE. This bit enables the automatic entering of the idle state bit IDLE will be set after a wrong hall event has been detected bit WHE is set . During the idle state the bit field MCMP is automatically cleared.
  [13] ENWHE — Enable Interrupt for Wrong Hall Event ENWHE
  [12] ENCHE — Enable Interrupt for Correct Hall Event ENCHE
  [10] ENTRPF — Enable Interrupt for Trap Flag ENTRPF
  [9] ENT13PM — Enable Interrupt for T13 Period Match ENT13PM
  [8] ENT13CM — Enable Interrupt for T13 Compare Match ENT13CM
  [7] ENT12PM — Enable Interrupt for T12 Period Match ENT12PM
  [6] ENT12OM — Enable Interrupt for T12 One Match ENT12OM
  [5] ENCC62F — Capture Compare Match Falling Edge Interrupt Enable for Channel CC6x ENCC6xF x 0 1 2
  [4] ENCC62R — Capture Compare Match Rising Edge Interrupt Enable for Channel CC6x ENCC6xF x 0 1 2
  [3] ENCC61F — Capture Compare Match Falling Edge Interrupt Enable for Channel CC6x ENCC6xF x 0 1 2
  [2] ENCC61R — Capture Compare Match Rising Edge Interrupt Enable for Channel CC6x ENCC6xF x 0 1 2
  [1] ENCC60F — Capture Compare Match Falling Edge Interrupt Enable for Channel CC6x ENCC6xF x 0 1 2
  [0] ENCC60R — Capture Compare Match Rising Edge Interrupt Enable for Channel CC6x ENCC6xF x 0 1 2
0xE8 OCS access per field — OCDS Control and Status Register resetvalue={PowerOn Reset:0x0,Debug Reset:0x0}
  [29] SUSSTA ro — Suspend State SUSSTA
  [28] SUS_P wo — SUS Write Protection SUS P. SUS is only written when SUS P is 1 otherwise unchanged. Read as 0.
  [27:24] SUS rw — OCDS Suspend Control SUS. Controls the sensitivity to the suspend signal coming from the OCDS Trigger Switch OTGS Effects of soft suspend options on CCU6 Functional Blocks are described in section CROSSREFERENCE
  [3] TG_P wo — TGS TGB Write Protection TG P. TGS and TGB are only written when TG P is 1 otherwise unchanged. Read as 0.
  [2] TGB rw — OTGB0 1 Bus Select TGB
  [1:0] TGS rw — Trigger Set for OTGB0 1 TGS
0xEC KRSTCLR wo — Kernel Reset Status Clear Register resetvalue={Application Reset:0x0}
  [0] CLR — Kernel Reset Status Clear CLR. Read always as 0.
0xF0 KRST1 — Kernel Reset Register 1 resetvalue={Application Reset:0x0}
  [0] RST — Kernel Reset RST. This reset bit can be used to request for a kernel reset. The kernel reset will be executed if the reset bits of both kernel reset registers are set. The RST bit will be cleared re set to 0 by the BPI after the kernel reset was executed.
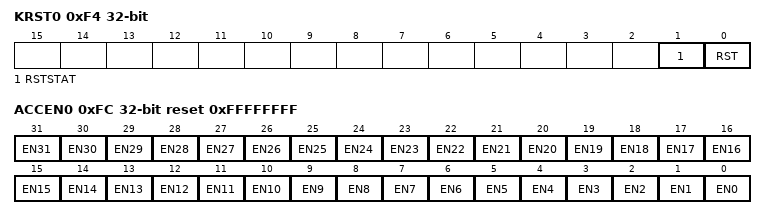
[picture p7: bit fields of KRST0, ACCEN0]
0xF4 KRST0 access per field — Kernel Reset Register 0 resetvalue={Application Reset:0x0}
  [1] RSTSTAT ro — Kernel Reset Status RSTSTAT. This bit indicates wether a kernel reset was executed or not. This bit is set after the execution of a kernel reset in the same clock cycle in which the reset bits are cleared. This bit can be cleared by writing with 180 1 180 to the CLR bit in the related KRSTCLR register.
  [0] RST rw — Kernel Reset RST. This reset bit can be used to request for a kernel reset. The kernel reset will be executed if the reset bits of both kernel registers are set. The RST bit will be cleared re set to 0 by the BPI after the kernel reset was executed.
0xFC ACCEN0 reset 0xFFFFFFFF — Access Enable Register 0 resetvalue={Application Reset:0x0FFFFFFFF}
  [n] EN{n} (n=0..31) — Access Enable for Master TAG ID 31 EN31. This bit enables write access to the module kernel addresses for transactions with the Master TAG ID y

## CCU61 — CCU6
Base 0xF0002B00
Registers as CCU60, without MOSEL.
